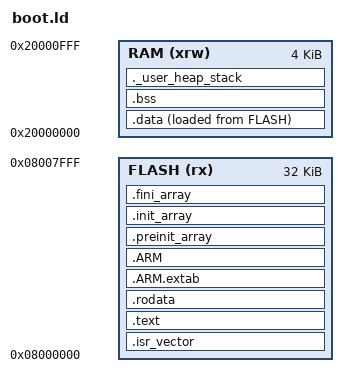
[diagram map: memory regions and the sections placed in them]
_Min_Heap_Size = 0;      /* required amount of heap  */
_Min_Stack_Size = 0x400; /* required amount of stack */

MEMORY
{
    FLASH (rx)      : ORIGIN = 0x08000000, LENGTH = 32K
    RAM (xrw)       : ORIGIN = 0x20000000, LENGTH = 4K
}

__ram_start__           = ORIGIN(RAM);
__ram_size__            = LENGTH(RAM);
_estack             = __ram_start__ + __ram_size__;

ENTRY(Reset_Handler)

SECTIONS
{
  /* The startup code goes first into FLASH */
  .isr_vector :
  {
    . = ALIGN(4);
    KEEP(*(.isr_vector))
    . = ALIGN(4);
  } >FLASH

  /* The program code and other data goes into FLASH */
  .text :
  {
    . = ALIGN(4);
    *(.text)
    *(.text*)
    *(.glue_7)
    *(.glue_7t)
    *(.eh_frame)

    KEEP (*(.init))
    KEEP (*(.fini))

    . = ALIGN(4);
    _etext = .;
  } >FLASH

  /* Constant data goes into FLASH */
  .rodata :
  {
    . = ALIGN(4);
    *(.rodata)
    *(.rodata*)
    KEEP(*(.rodata.version))
    . = ALIGN(4);
  } >FLASH

  .ARM.extab   : { *(.ARM.extab* .gnu.linkonce.armextab.*) } >FLASH
  .ARM : {
    __exidx_start = .;
    *(.ARM.exidx*)
    __exidx_end = .;
  } >FLASH

  .preinit_array     :
  {
    PROVIDE_HIDDEN (__preinit_array_start = .);
    KEEP (*(.preinit_array*))
    PROVIDE_HIDDEN (__preinit_array_end = .);
  } >FLASH
  .init_array :
  {
    PROVIDE_HIDDEN (__init_array_start = .);
    KEEP (*(SORT(.init_array.*)))
    KEEP (*(.init_array*))
    PROVIDE_HIDDEN (__init_array_end = .);
  } >FLASH
  .fini_array :
  {
    PROVIDE_HIDDEN (__fini_array_start = .);
    KEEP (*(SORT(.fini_array.*)))
    KEEP (*(.fini_array*))
    PROVIDE_HIDDEN (__fini_array_end = .);
  } >FLASH

  /* used by the startup to initialize data */
  _sidata = LOADADDR(.data);

  /* Initialized data sections goes into RAM, load LMA copy after code */
  .data : 
  {
    . = ALIGN(4);
    _sdata = .;
    *(.data)
    *(.data*)

    . = ALIGN(4);
    _edata = .;
  } >RAM AT> FLASH

  
  /* Uninitialized data section */
  . = ALIGN(4);
  .bss :
  {
    _sbss = .;
    __bss_start__ = _sbss;
    *(.bss)
    *(.bss*)
    *(COMMON)

    . = ALIGN(4);
    _ebss = .;
    __bss_end__ = _ebss;
  } >RAM

  /* User_heap_stack section, used to check that there is enough RAM left */
  ._user_heap_stack :
  {
    . = ALIGN(8);
    PROVIDE ( end = . );
    PROVIDE ( _end = . );
    . = . + _Min_Heap_Size;
    . = . + _Min_Stack_Size;
    . = ALIGN(8);
  } >RAM
  

  /* Remove information from the standard libraries */
  /DISCARD/ :
  {
    libc.a ( * )
    libm.a ( * )
    libgcc.a ( * )
  }

  .ARM.attributes 0 : { *(.ARM.attributes) }
}
